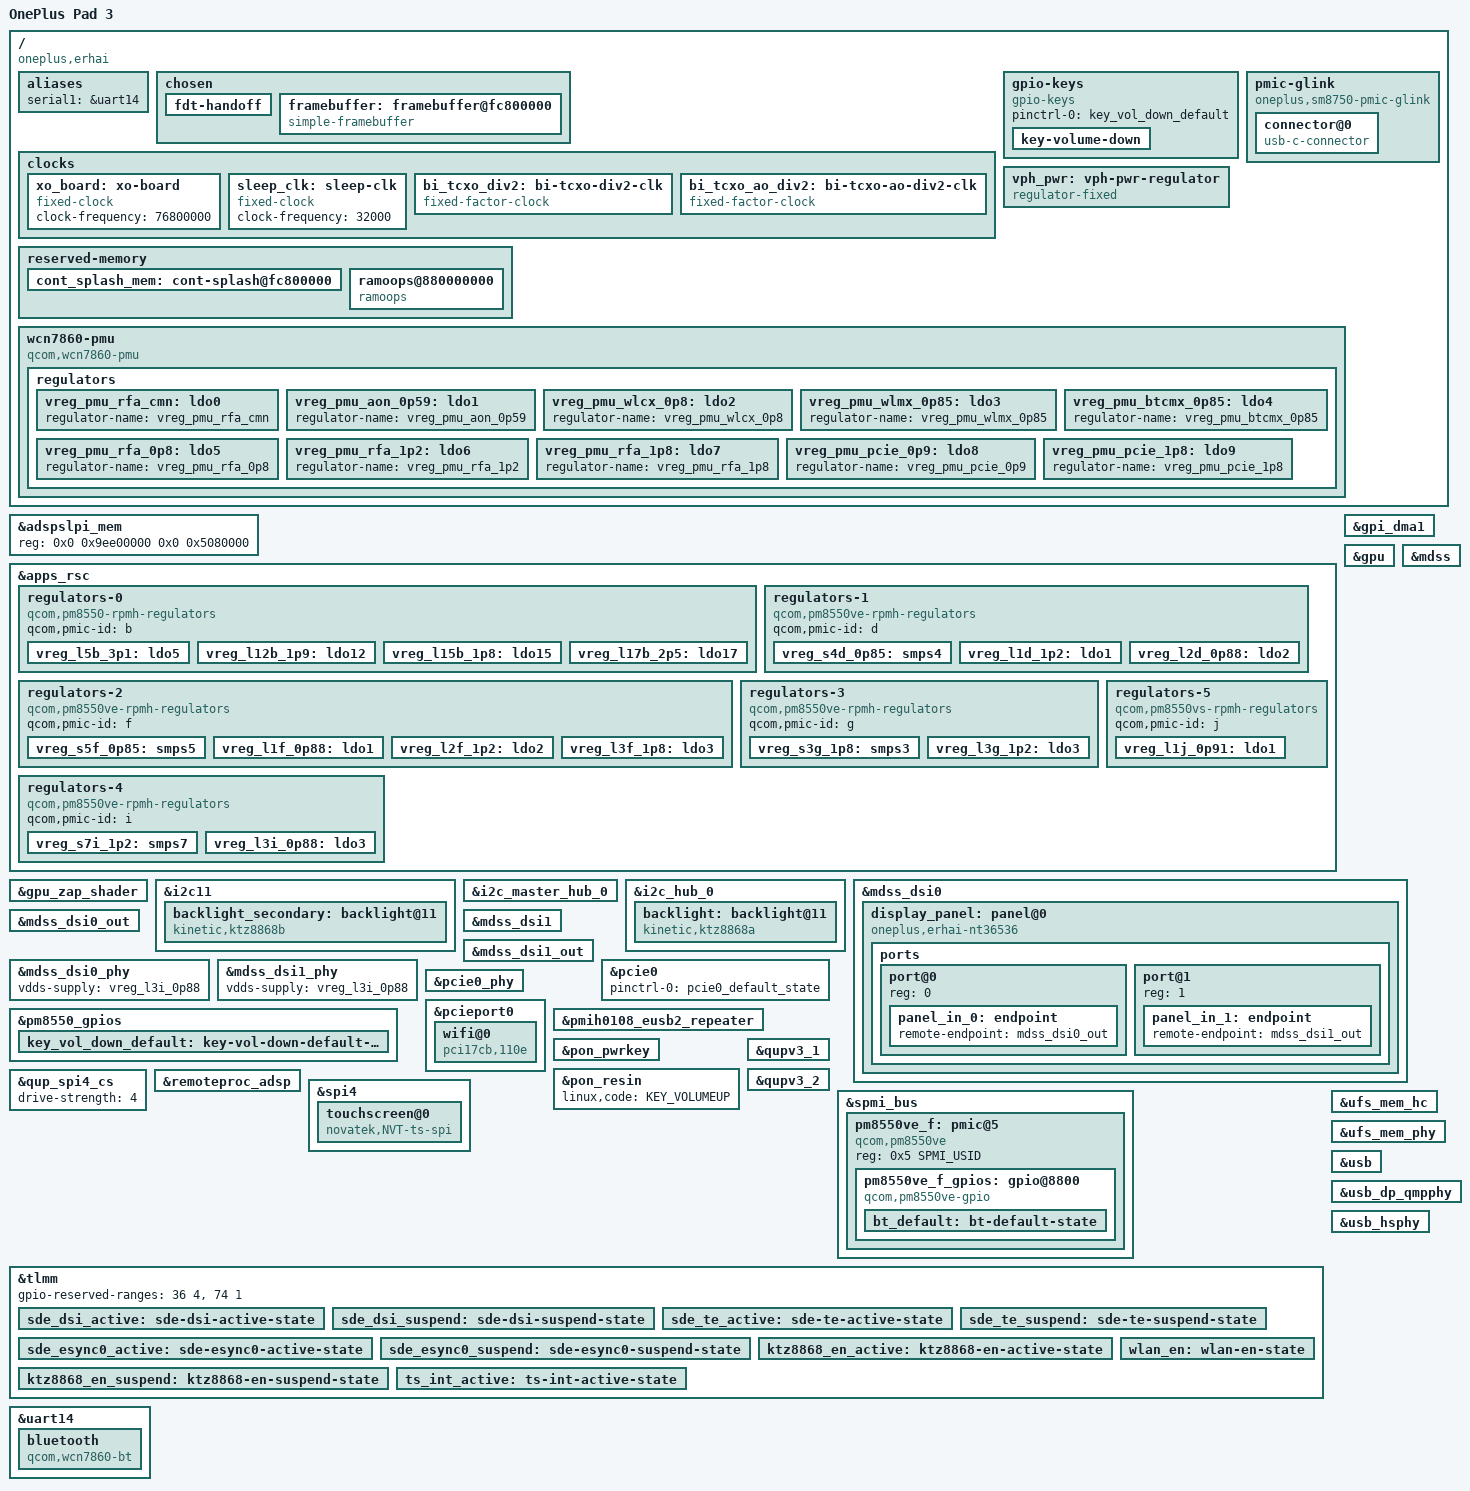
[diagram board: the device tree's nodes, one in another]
// SPDX-License-Identifier: BSD-3-Clause
/*
 * OnePlus Pad 3 (erhai)
 *
 * The rails, tuning values and GPIOs below are the ones the stock
 * bootloader tree of this tablet gives its own kernel. Rails that are not
 * described here keep the state the bootloader left them in; among the
 * display ones, the panel's logic and analog supplies, and its LCD bias,
 * which the backlight controller generates and the bootloader leaves on.
 */

/dts-v1/;

#include <dt-bindings/gpio/gpio.h>
#include <dt-bindings/input/linux-event-codes.h>
#include <dt-bindings/pinctrl/qcom,pmic-gpio.h>
#include <dt-bindings/regulator/qcom,rpmh-regulator.h>
#include <dt-bindings/spmi/spmi.h>
#include "sm8750.dtsi"
#include "pm8550.dtsi"
#include "pmih0108.dtsi"
#include "pmk8550.dtsi"

/ {
	model = "OnePlus Pad 3";
	compatible = "oneplus,erhai", "qcom,sm8750";
	chassis-type = "tablet";

	/*
	 * The GENI UART driver numbers its ports from the serial aliases and
	 * fails to probe without any. serial1 as on the other SM8750 boards,
	 * where serial0 is the debug UART.
	 */
	aliases {
		serial1 = &uart14;
	};

	chosen {
		#address-cells = <2>;
		#size-cells = <2>;
		ranges;

		/* The init_boot every phone shares carries the boot userspace. */
		bootargs = "rdinit=/init console=tty0 panic=0 loglevel=7 log_buf_len=2M bootconfig";

		/*
		 * The bootloader picks one of the erhai overlays of dtbo, all on
		 * the same SunP base tree; its project id names the tablet.
		 */
		fdt-handoff {
			stock-compatible = "qcom,sun", "qcom,sunp";
			stock-bootargs = "oplusboot.prjname=24924",
					 "oplusboot.prjname=24926",
					 "oplusboot.prjname=24974",
					 "oplusboot.prjname=24976";
			keep-initrd;
		};

		/* Bootloader splash, left running by ABL (XN242, two video-mode links) */
		framebuffer: framebuffer@fc800000 {
			compatible = "simple-framebuffer";
			reg = <0x0 0xfc800000 0x0 (3392 * 2400 * 4)>;
			width = <3392>;
			height = <2400>;
			stride = <(3392 * 4)>;
			format = "a8r8g8b8";

			/*
			 * Held while no display driver runs, or the boot clean-up
			 * of unused clocks and power domains stops the scanout.
			 */
			clocks = <&gcc GCC_DISP_HF_AXI_CLK>,
				 <&dispcc DISP_CC_MDSS_AHB_CLK>,
				 <&dispcc DISP_CC_MDSS_MDP_CLK>,
				 <&dispcc DISP_CC_MDSS_VSYNC_CLK>,
				 <&dispcc DISP_CC_MDSS_ESC0_CLK>,
				 <&dispcc DISP_CC_MDSS_BYTE0_CLK>,
				 <&dispcc DISP_CC_MDSS_BYTE0_INTF_CLK>,
				 <&dispcc DISP_CC_MDSS_PCLK0_CLK>,
				 <&dispcc DISP_CC_MDSS_ESC1_CLK>,
				 <&dispcc DISP_CC_MDSS_BYTE1_CLK>,
				 <&dispcc DISP_CC_MDSS_BYTE1_INTF_CLK>,
				 <&dispcc DISP_CC_MDSS_PCLK1_CLK>;
			power-domains = <&dispcc MDSS_GDSC>,
					<&dispcc MDSS_INT2_GDSC>;
			/* The level of the fastest MDP clock of mdp_opp_table */
			required-opps = <&rpmhpd_opp_nom_l1>, <&rpmhpd_opp_nom_l1>;
		};
	};

	clocks {
		xo_board: xo-board {
			compatible = "fixed-clock";
			clock-frequency = <76800000>;
			#clock-cells = <0>;
		};

		sleep_clk: sleep-clk {
			compatible = "fixed-clock";
			clock-frequency = <32000>;
			#clock-cells = <0>;
		};

		bi_tcxo_div2: bi-tcxo-div2-clk {
			compatible = "fixed-factor-clock";
			#clock-cells = <0>;

			clocks = <&rpmhcc RPMH_CXO_CLK>;
			clock-mult = <1>;
			clock-div = <2>;
		};

		bi_tcxo_ao_div2: bi-tcxo-ao-div2-clk {
			compatible = "fixed-factor-clock";
			#clock-cells = <0>;

			clocks = <&rpmhcc RPMH_CXO_CLK_A>;
			clock-mult = <1>;
			clock-div = <2>;
		};
	};

	gpio-keys {
		compatible = "gpio-keys";

		pinctrl-0 = <&key_vol_down_default>;
		pinctrl-names = "default";

		key-volume-down {
			label = "Volume Down";
			linux,code = <KEY_VOLUMEDOWN>;
			gpios = <&pm8550_gpios 6 GPIO_ACTIVE_LOW>;
			debounce-interval = <32>;
			linux,can-disable;
			wakeup-source;
		};
	};

	vph_pwr: vph-pwr-regulator {
		compatible = "regulator-fixed";

		regulator-name = "vph_pwr";
		regulator-min-microvolt = <3700000>;
		regulator-max-microvolt = <3700000>;

		regulator-always-on;
		regulator-boot-on;
	};

	pmic-glink {
		compatible = "oneplus,sm8750-pmic-glink",
			     "qcom,sm8750-pmic-glink",
			     "qcom,sm8550-pmic-glink",
			     "qcom,pmic-glink";
		#address-cells = <1>;
		#size-cells = <0>;

		connector@0 {
			compatible = "usb-c-connector";
			reg = <0>;

			power-role = "dual";
			data-role = "dual";
		};
	};

	reserved-memory {
		/* The splash the bootloader scans out, splash_region downstream. */
		cont_splash_mem: cont-splash@fc800000 {
			reg = <0x0 0xfc800000 0x0 0x2b00000>;
			iommu-addresses = <&mdss 0x0 0xfc800000 0x0 0x2b00000>;
			no-map;
		};

		/*
		 * Where the stock kernel places its dynamic ramoops region, with
		 * its zones: no dmesg records, the console, then pmsg. Recovery
		 * then shows this kernel's console after a warm reset.
		 */
		ramoops@880000000 {
			compatible = "ramoops";
			reg = <0x8 0x80000000 0x0 0x240000>;
			console-size = <0x40000>;
			pmsg-size = <0x200000>;
			no-map;
		};
	};

	/*
	 * The WCN7860 Wi-Fi/Bluetooth combo, on the rails and enable lines
	 * the stock kernel gives it. The Bluetooth enable line is on the
	 * PM8550VE-F GPIO 3; the stock fdt drives it from the vendor
	 * bluetooth driver through the same "bt_uwb_en" pinctrl state.
	 */
	wcn7860-pmu {
		compatible = "qcom,wcn7860-pmu";

		pinctrl-0 = <&wlan_en>, <&bt_default>;
		pinctrl-names = "default";

		wlan-enable-gpios = <&tlmm 16 GPIO_ACTIVE_HIGH>;
		bt-enable-gpios = <&pm8550ve_f_gpios 3 GPIO_ACTIVE_HIGH>;

		vddio-supply = <&vreg_l3f_1p8>;
		vddio1p2-supply = <&vreg_l2f_1p2>;
		vddaon-supply = <&vreg_s4d_0p85>;
		vdddig-supply = <&vreg_s5f_0p85>;
		vddrfa1p2-supply = <&vreg_s7i_1p2>;
		vddrfa1p8-supply = <&vreg_s3g_1p8>;

		clocks = <&rpmhcc RPMH_RF_CLK1>;

		regulators {
			vreg_pmu_rfa_cmn: ldo0 {
				regulator-name = "vreg_pmu_rfa_cmn";
			};

			vreg_pmu_aon_0p59: ldo1 {
				regulator-name = "vreg_pmu_aon_0p59";
			};

			vreg_pmu_wlcx_0p8: ldo2 {
				regulator-name = "vreg_pmu_wlcx_0p8";
			};

			vreg_pmu_wlmx_0p85: ldo3 {
				regulator-name = "vreg_pmu_wlmx_0p85";
			};

			vreg_pmu_btcmx_0p85: ldo4 {
				regulator-name = "vreg_pmu_btcmx_0p85";
			};

			vreg_pmu_rfa_0p8: ldo5 {
				regulator-name = "vreg_pmu_rfa_0p8";
			};

			vreg_pmu_rfa_1p2: ldo6 {
				regulator-name = "vreg_pmu_rfa_1p2";
			};

			vreg_pmu_rfa_1p8: ldo7 {
				regulator-name = "vreg_pmu_rfa_1p8";
			};

			vreg_pmu_pcie_0p9: ldo8 {
				regulator-name = "vreg_pmu_pcie_0p9";
			};

			vreg_pmu_pcie_1p8: ldo9 {
				regulator-name = "vreg_pmu_pcie_1p8";
			};
		};
	};
};

/* The ADSP firmware of this tablet loads 0x5080000 bytes from the carveout. */
&adspslpi_mem {
	reg = <0x0 0x9ee00000 0x0 0x5080000>;
};

&apps_rsc {
	regulators-0 {
		compatible = "qcom,pm8550-rpmh-regulators";
		qcom,pmic-id = "b";

		vreg_l5b_3p1: ldo5 {
			regulator-name = "vreg_l5b_3p1";
			regulator-min-microvolt = <3100000>;
			regulator-max-microvolt = <3148000>;
			regulator-initial-mode = <RPMH_REGULATOR_MODE_HPM>;
		};

		/*
		 * Stock asks 1.9 V, its maximum for this rail, which falls
		 * between two 8 mV steps of this LDO: the step below.
		 */
		vreg_l12b_1p9: ldo12 {
			regulator-name = "vreg_l12b_1p9";
			regulator-min-microvolt = <1896000>;
			regulator-max-microvolt = <1896000>;
			regulator-initial-mode = <RPMH_REGULATOR_MODE_HPM>;
		};

		vreg_l15b_1p8: ldo15 {
			regulator-name = "vreg_l15b_1p8";
			regulator-min-microvolt = <1800000>;
			regulator-max-microvolt = <1800000>;
			regulator-initial-mode = <RPMH_REGULATOR_MODE_HPM>;
		};

		vreg_l17b_2p5: ldo17 {
			regulator-name = "vreg_l17b_2p5";
			regulator-min-microvolt = <2504000>;
			regulator-max-microvolt = <2504000>;
			regulator-initial-mode = <RPMH_REGULATOR_MODE_HPM>;
		};
	};

	regulators-1 {
		compatible = "qcom,pm8550ve-rpmh-regulators";
		qcom,pmic-id = "d";

		/* The stock Wi-Fi driver asks 876-1036 mV of the WCN's AON rail. */
		vreg_s4d_0p85: smps4 {
			regulator-name = "vreg_s4d_0p85";
			regulator-min-microvolt = <876000>;
			regulator-max-microvolt = <1036000>;
			regulator-initial-mode = <RPMH_REGULATOR_MODE_HPM>;
		};

		vreg_l1d_1p2: ldo1 {
			regulator-name = "vreg_l1d_1p2";
			regulator-min-microvolt = <1200000>;
			regulator-max-microvolt = <1200000>;
			regulator-initial-mode = <RPMH_REGULATOR_MODE_HPM>;
		};

		vreg_l2d_0p88: ldo2 {
			regulator-name = "vreg_l2d_0p88";
			regulator-min-microvolt = <880000>;
			regulator-max-microvolt = <912000>;
			regulator-initial-mode = <RPMH_REGULATOR_MODE_HPM>;
		};
	};

	regulators-2 {
		compatible = "qcom,pm8550ve-rpmh-regulators";
		qcom,pmic-id = "f";

		/* The stock Wi-Fi driver asks 876-1000 mV of the WCN's digital rail. */
		vreg_s5f_0p85: smps5 {
			regulator-name = "vreg_s5f_0p85";
			regulator-min-microvolt = <876000>;
			regulator-max-microvolt = <1000000>;
			regulator-initial-mode = <RPMH_REGULATOR_MODE_HPM>;
		};

		vreg_l1f_0p88: ldo1 {
			regulator-name = "vreg_l1f_0p88";
			regulator-min-microvolt = <880000>;
			regulator-max-microvolt = <920000>;
			regulator-initial-mode = <RPMH_REGULATOR_MODE_HPM>;
		};

		vreg_l2f_1p2: ldo2 {
			regulator-name = "vreg_l2f_1p2";
			regulator-min-microvolt = <1200000>;
			regulator-max-microvolt = <1200000>;
			regulator-initial-mode = <RPMH_REGULATOR_MODE_HPM>;
		};

		vreg_l3f_1p8: ldo3 {
			regulator-name = "vreg_l3f_1p8";
			regulator-min-microvolt = <1800000>;
			regulator-max-microvolt = <1800000>;
			regulator-initial-mode = <RPMH_REGULATOR_MODE_HPM>;
		};
	};

	regulators-3 {
		compatible = "qcom,pm8550ve-rpmh-regulators";
		qcom,pmic-id = "g";

		/*
		 * The stock Wi-Fi driver asks 1.86-2 V of the WCN's RF rail:
		 * from 1856 mV, the step below.
		 */
		vreg_s3g_1p8: smps3 {
			regulator-name = "vreg_s3g_1p8";
			regulator-min-microvolt = <1856000>;
			regulator-max-microvolt = <2000000>;
			regulator-initial-mode = <RPMH_REGULATOR_MODE_LPM>;
		};

		vreg_l3g_1p2: ldo3 {
			regulator-name = "vreg_l3g_1p2";
			regulator-min-microvolt = <1200000>;
			regulator-max-microvolt = <1256000>;
			regulator-initial-mode = <RPMH_REGULATOR_MODE_HPM>;
		};
	};

	regulators-4 {
		compatible = "qcom,pm8550ve-rpmh-regulators";
		qcom,pmic-id = "i";

		/* The stock Wi-Fi driver asks 1312-1340 mV of the WCN's RF rail. */
		vreg_s7i_1p2: smps7 {
			regulator-name = "vreg_s7i_1p2";
			regulator-min-microvolt = <1312000>;
			regulator-max-microvolt = <1340000>;
			regulator-initial-mode = <RPMH_REGULATOR_MODE_HPM>;
		};

		vreg_l3i_0p88: ldo3 {
			regulator-name = "vreg_l3i_0p88";
			regulator-min-microvolt = <880000>;
			regulator-max-microvolt = <912000>;
			regulator-initial-mode = <RPMH_REGULATOR_MODE_HPM>;
		};
	};

	regulators-5 {
		compatible = "qcom,pm8550vs-rpmh-regulators";
		qcom,pmic-id = "j";

		/* The stock UFS PHY driver asks 912 mV of this 880-920 mV rail. */
		vreg_l1j_0p91: ldo1 {
			regulator-name = "vreg_l1j_0p91";
			regulator-min-microvolt = <912000>;
			regulator-max-microvolt = <920000>;
			regulator-initial-mode = <RPMH_REGULATOR_MODE_HPM>;
		};
	};
};

/* The touchscreen's SPI engine runs in GSI mode, on GPI DMA. */
&gpi_dma1 {
	status = "okay";
};

&gpu {
	status = "okay";
};

/*
 * The zap shader is signed for OnePlus; the stock vendor partition keeps it
 * as gen80000_zap.mbn.
 */
&gpu_zap_shader {
	firmware-name = "qcom/sm8750/erhai/gen80000_zap.mbn";
};

/*
 * The stock kernel runs the panel on two DSI controllers, four lanes each,
 * the second in sync with the first, and lights it with two KTZ8868
 * controllers on two I2C buses.
 */
&i2c11 {
	status = "okay";

	backlight_secondary: backlight@11 {
		compatible = "kinetic,ktz8868b";
		reg = <0x11>;

		vin-supply = <&vph_pwr>;
		vddio-supply = <&vreg_l12b_1p9>;

		status = "okay";
	};
};

&i2c_master_hub_0 {
	status = "okay";
};

&i2c_hub_0 {
	status = "okay";

	backlight: backlight@11 {
		compatible = "kinetic,ktz8868a";
		reg = <0x11>;

		enable-gpios = <&tlmm 15 GPIO_ACTIVE_HIGH>;

		vin-supply = <&vph_pwr>;
		vddio-supply = <&vreg_l12b_1p9>;

		pinctrl-0 = <&ktz8868_en_active>;
		pinctrl-1 = <&ktz8868_en_suspend>;
		pinctrl-names = "default", "sleep";

		status = "okay";
	};
};

&mdss {
	/*
	 * The display is handed over as the bootloader runs it, reading the
	 * splash memory, and with both the power domains the bootloader has
	 * on: without the second one the control path sat in reset, and no
	 * frame of ours came out until the whole display was reset.
	 */
	memory-region = <&cont_splash_mem>;
	power-domains = <&dispcc MDSS_GDSC>, <&dispcc MDSS_INT2_GDSC>;

	status = "okay";
};

&mdss_dsi0 {
	vdda-supply = <&vreg_l3g_1p2>;

	qcom,dual-dsi-mode;
	qcom,sync-dual-dsi;
	qcom,master-dsi;

	status = "okay";

	display_panel: panel@0 {
		compatible = "oneplus,erhai-nt36536", "novatek,nt36536";
		reg = <0>;

		reset-gpios = <&tlmm 98 GPIO_ACTIVE_LOW>;

		vddio-supply = <&vreg_l12b_1p9>;

		/* The LCD bias comes from the backlight controller, which
		 * the boost converters feed.
		 */
		avdd-supply = <&vph_pwr>;
		avee-supply = <&vph_pwr>;

		backlight = <&backlight>;

		pinctrl-0 = <&sde_dsi_active &sde_te_active &sde_esync0_active>;
		pinctrl-1 = <&sde_dsi_suspend &sde_te_suspend &sde_esync0_suspend>;
		pinctrl-names = "default", "sleep";

		ports {
			#address-cells = <1>;
			#size-cells = <0>;

			port@0 {
				reg = <0>;

				panel_in_0: endpoint {
					remote-endpoint = <&mdss_dsi0_out>;
				};
			};

			port@1 {
				reg = <1>;

				panel_in_1: endpoint {
					remote-endpoint = <&mdss_dsi1_out>;
				};
			};
		};
	};
};

&mdss_dsi0_out {
	data-lanes = <0 1 2 3>;
	remote-endpoint = <&panel_in_0>;
};

&mdss_dsi0_phy {
	vdds-supply = <&vreg_l3i_0p88>;

	status = "okay";
};

&mdss_dsi1 {
	vdda-supply = <&vreg_l3g_1p2>;

	qcom,dual-dsi-mode;
	qcom,sync-dual-dsi;

	/* The second controller is in sync with the first, so its PLL
	 * clocks come from the first PHY.
	 */
	clocks = <&dispcc DISP_CC_MDSS_BYTE1_CLK>,
		 <&dispcc DISP_CC_MDSS_BYTE1_INTF_CLK>,
		 <&dispcc DISP_CC_MDSS_PCLK1_CLK>,
		 <&dispcc DISP_CC_MDSS_ESC1_CLK>,
		 <&dispcc DISP_CC_MDSS_AHB_CLK>,
		 <&gcc GCC_DISP_HF_AXI_CLK>,
		 <&mdss_dsi0_phy DSI_PIXEL_PLL_CLK>,
		 <&mdss_dsi0_phy DSI_BYTE_PLL_CLK>,
		 <&dispcc DISP_CC_ESYNC1_CLK>,
		 <&dispcc DISP_CC_OSC_CLK>,
		 <&dispcc DISP_CC_MDSS_BYTE1_CLK_SRC>,
		 <&dispcc DISP_CC_MDSS_PCLK1_CLK_SRC>;

	status = "okay";
};

&mdss_dsi1_out {
	data-lanes = <0 1 2 3>;
	remote-endpoint = <&panel_in_1>;
};

&mdss_dsi1_phy {
	vdds-supply = <&vreg_l3i_0p88>;

	status = "okay";
};

&pcie0 {
	pinctrl-0 = <&pcie0_default_state>;
	pinctrl-names = "default";

	status = "okay";
};

&pcie0_phy {
	vdda-phy-supply = <&vreg_l1f_0p88>;
	vdda-pll-supply = <&vreg_l3g_1p2>;

	status = "okay";
};

&pcieport0 {
	wake-gpios = <&tlmm 104 GPIO_ACTIVE_LOW>;
	reset-gpios = <&tlmm 102 GPIO_ACTIVE_LOW>;

	wifi@0 {
		compatible = "pci17cb,110e";
		reg = <0x10000 0x0 0x0 0x0 0x0>;

		vddrfacmn-supply = <&vreg_pmu_rfa_cmn>;
		vddaon-supply = <&vreg_pmu_aon_0p59>;
		vddwlcx-supply = <&vreg_pmu_wlcx_0p8>;
		vddwlmx-supply = <&vreg_pmu_wlmx_0p85>;
		vddrfa0p8-supply = <&vreg_pmu_rfa_0p8>;
		vddrfa1p2-supply = <&vreg_pmu_rfa_1p2>;
		vddrfa1p8-supply = <&vreg_pmu_rfa_1p8>;
		vddpcie0p9-supply = <&vreg_pmu_pcie_0p9>;
		vddpcie1p8-supply = <&vreg_pmu_pcie_1p8>;
	};
};

&pm8550_gpios {
	key_vol_down_default: key-vol-down-default-state {
		pins = "gpio6";
		function = "normal";
		input-enable;
		bias-pull-up;
		power-source = <1>;
	};
};

&pmih0108_eusb2_repeater {
	qcom,tune-usb2-amplitude = /bits/ 8 <0xb>;
	qcom,tune-usb2-disc-thres = /bits/ 8 <0x7>;
	qcom,tune-usb2-preem = /bits/ 8 <0x3>;
	qcom,squelch-detector-bp = <(-2000)>;

	vdd18-supply = <&vreg_l15b_1p8>;
	vdd3-supply = <&vreg_l5b_3p1>;
};

&pon_pwrkey {
	status = "okay";
};

&pon_resin {
	linux,code = <KEY_VOLUMEUP>;

	status = "okay";
};

/* The stock kernel drives the touchscreen's chip select at 4 mA. */
&qup_spi4_cs {
	drive-strength = <4>;
};

/* The touchscreen's bus, spi4, is on this wrapper. */
&qupv3_1 {
	status = "okay";
};

/* The second backlight controller's bus, i2c11, is on this wrapper. */
&qupv3_2 {
	status = "okay";
};

&remoteproc_adsp {
	firmware-name = "qcom/sm8750/oneplus/erhai/adsp.mdt",
			"qcom/sm8750/oneplus/erhai/adsp_dtb.mdt";

	status = "okay";
};

&spi4 {
	status = "okay";

	/*
	 * NT36536 in the panel (in-cell): powered and reset with the panel,
	 * so it has no supplies and no reset line of its own. The controller
	 * has no flash and takes its firmware at every power-on.
	 */
	touchscreen@0 {
		compatible = "novatek,NVT-ts-spi";
		reg = <0>;

		spi-max-frequency = <12000000>;
		irq-gpios = <&tlmm 162 GPIO_ACTIVE_HIGH>;

		pinctrl-0 = <&ts_int_active>;
		pinctrl-names = "default";

		novatek,pen-support;

		panel = <&display_panel>;

		firmware-name = "novatek/erhai/novatek_nt36536_fw.bin";
		/* As its firmware reports them: x along the panel's long side */
		touchscreen-size-x = <33920>;
		touchscreen-size-y = <24000>;
	};
};

&spmi_bus {
	/*
	 * Only the PM8550VE-F GPIOs are described: the WCN7860 Bluetooth
	 * enable line is its GPIO 3.
	 */
	pm8550ve_f: pmic@5 {
		compatible = "qcom,pm8550ve", "qcom,spmi-pmic";
		reg = <0x5 SPMI_USID>;
		#address-cells = <1>;
		#size-cells = <0>;

		pm8550ve_f_gpios: gpio@8800 {
			compatible = "qcom,pm8550ve-gpio", "qcom,spmi-gpio";
			reg = <0x8800>;
			gpio-controller;
			gpio-ranges = <&pm8550ve_f_gpios 0 0 6>;
			#gpio-cells = <2>;
			interrupt-controller;
			#interrupt-cells = <2>;
		};
	};
};

&pm8550ve_f_gpios {
	bt_default: bt-default-state {
		pins = "gpio3";
		function = "normal";
		input-disable;
		output-enable;
		output-low;
		bias-disable;
		power-source = <1>;
	};
};

&tlmm {
	/* Reserved I/Os that are not accessible from the application processor */
	gpio-reserved-ranges = <36 4>, <74 1>;

	/*
	 * The panel's reset, tearing-effect and sync lines, as the stock
	 * kernel sets them for its primary display, and the enable lines of
	 * the backlight controller. The panel driver takes the reset; the
	 * rest the bootloader already set, and the states hold them across
	 * suspend.
	 */
	sde_dsi_active: sde-dsi-active-state {
		pins = "gpio98";
		function = "gpio";
		drive-strength = <8>;
		bias-disable;
	};

	sde_dsi_suspend: sde-dsi-suspend-state {
		pins = "gpio98";
		function = "gpio";
		drive-strength = <2>;
		bias-pull-down;
	};

	sde_te_active: sde-te-active-state {
		pins = "gpio86";
		function = "mdp_vsync";
		drive-strength = <2>;
		bias-pull-down;
	};

	sde_te_suspend: sde-te-suspend-state {
		pins = "gpio86";
		function = "mdp_vsync";
		drive-strength = <2>;
		bias-pull-down;
	};

	sde_esync0_active: sde-esync0-active-state {
		pins = "gpio88";
		function = "gpio";
		drive-strength = <2>;
		bias-pull-down;
	};

	sde_esync0_suspend: sde-esync0-suspend-state {
		pins = "gpio88";
		function = "gpio";
		drive-strength = <2>;
		bias-pull-down;
	};

	ktz8868_en_active: ktz8868-en-active-state {
		pins = "gpio14", "gpio15", "gpio111";
		function = "gpio";
		drive-strength = <8>;
		bias-pull-up;
	};

	ktz8868_en_suspend: ktz8868-en-suspend-state {
		pins = "gpio14", "gpio15", "gpio111";
		function = "gpio";
		drive-strength = <8>;
		bias-pull-down;
	};

	wlan_en: wlan-en-state {
		pins = "gpio16";
		function = "gpio";
		drive-strength = <8>;
		bias-pull-down;
	};

	ts_int_active: ts-int-active-state {
		pins = "gpio162";
		function = "gpio";
		drive-strength = <8>;
		bias-disable;
	};
};

/*
 * The WCN7860 Bluetooth host interface. The stock fdt keeps this UART
 * enabled and its stock pinctrl states switch gpio24-27 to qup2_se6.
 * The Bluetooth enable line and the rails are driven by the
 * wcn7860-pmu power sequencer, which the PMU supplies tie it to.
 */
&uart14 {
	status = "okay";

	bluetooth {
		compatible = "qcom,wcn7860-bt";

		vddrfacmn-supply = <&vreg_pmu_rfa_cmn>;
		vddaon-supply = <&vreg_pmu_aon_0p59>;
		vddwlcx-supply = <&vreg_pmu_wlcx_0p8>;
		vddwlmx-supply = <&vreg_pmu_wlmx_0p85>;
		vddrfa0p8-supply = <&vreg_pmu_rfa_0p8>;
		vddrfa1p2-supply = <&vreg_pmu_rfa_1p2>;
		vddrfa1p8-supply = <&vreg_pmu_rfa_1p8>;

		max-speed = <3200000>;
	};
};

&ufs_mem_hc {
	reset-gpios = <&tlmm 215 GPIO_ACTIVE_LOW>;

	vcc-supply = <&vreg_l17b_2p5>;
	vcc-max-microamp = <1300000>;
	vccq-supply = <&vreg_l1d_1p2>;
	vccq-max-microamp = <1200000>;

	status = "okay";
};

&ufs_mem_phy {
	vdda-phy-supply = <&vreg_l1j_0p91>;
	vdda-pll-supply = <&vreg_l3g_1p2>;

	status = "okay";
};

&usb {
	/*
	 * Role changes from the Type-C port are not wired up yet: stay a
	 * high-speed peripheral.
	 */
	dr_mode = "peripheral";
	maximum-speed = "high-speed";
	/delete-property/ usb-role-switch;

	status = "okay";
};

&usb_dp_qmpphy {
	vdda-phy-supply = <&vreg_l2d_0p88>;
	vdda-pll-supply = <&vreg_l3g_1p2>;

	status = "okay";
};

&usb_hsphy {
	vdd-supply = <&vreg_l2d_0p88>;
	vdda12-supply = <&vreg_l3g_1p2>;

	phys = <&pmih0108_eusb2_repeater>;

	status = "okay";
};
